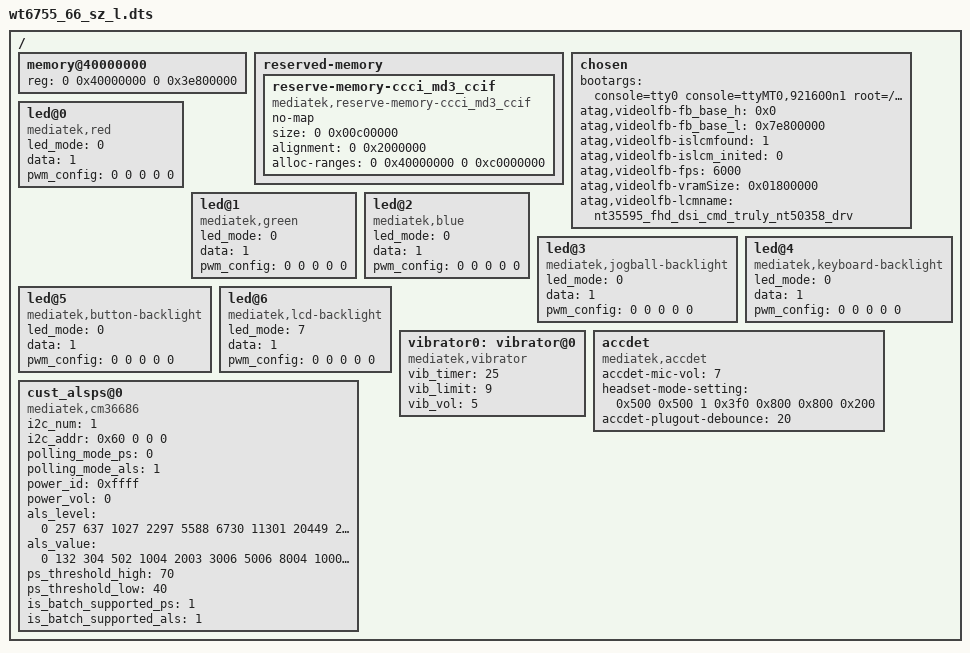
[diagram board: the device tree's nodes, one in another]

/dts-v1/;

#include "mt6755.dtsi"

/ {
	memory@40000000 {
		device_type = "memory";
		reg = <0 0x40000000 0 0x3e800000>;
	};

	reserved-memory {
		#address-cells = <2>;
		#size-cells = <2>;
		ranges;

		reserve-memory-ccci_md3_ccif {
			compatible = "mediatek,reserve-memory-ccci_md3_ccif";
			no-map;
			size = <0 0x00c00000>;
			alignment = <0 0x2000000>;
			alloc-ranges = <0 0x40000000 0 0xc0000000>;
		};
	};

	/* chosen */
	chosen {
		bootargs = "console=tty0 console=ttyMT0,921600n1 root=/dev/ram initrd=0x44000000,0x4b434e loglevel=8";

		/* fpga may has no lk, we need to specify display info here */
		/* fb buffer is reserved using this dts by memory node above */
		atag,videolfb-fb_base_h = <0x0>;
		atag,videolfb-fb_base_l = <0x7e800000>;
		atag,videolfb-islcmfound = <1>;
		/* because no lk, so lcm is not inited */
		atag,videolfb-islcm_inited = <0>;
		atag,videolfb-fps= <6000>;
		atag,videolfb-vramSize= <0x01800000>;
		atag,videolfb-lcmname= "nt35595_fhd_dsi_cmd_truly_nt50358_drv";
	};
	led@0 {
		compatible = "mediatek,red";
		led_mode = <0>;
		data = <1>;
		pwm_config = <0 0 0 0 0>;
	};
	led@1 {
		compatible = "mediatek,green";
		led_mode = <0>;
		data = <1>;
		pwm_config = <0 0 0 0 0>;
	};
	led@2 {
		compatible = "mediatek,blue";
		led_mode = <0>;
		data = <1>;
		pwm_config = <0 0 0 0 0>;
	};
	led@3 {
		compatible = "mediatek,jogball-backlight";
		led_mode = <0>;
		data = <1>;
		pwm_config = <0 0 0 0 0>;
	};
	led@4 {
		compatible = "mediatek,keyboard-backlight";
		led_mode = <0>;
		data = <1>;
		pwm_config = <0 0 0 0 0>;
	};
	led@5 {
		compatible = "mediatek,button-backlight";
		led_mode = <0>;
		data = <1>;
		pwm_config = <0 0 0 0 0>;
	};
	led@6 {
		compatible = "mediatek,lcd-backlight";
		led_mode = <7>;
		data = <1>;
		pwm_config = <0 0 0 0 0>;
	};
	vibrator0:vibrator@0 {
		compatible = "mediatek,vibrator";
		vib_timer = <25>;
		vib_limit = <9>;
		vib_vol= <5>;
	};
	accdet {
		compatible = "mediatek,accdet";
		accdet-mic-vol = <7>;
		headset-mode-setting = <0x500 0x500 1 0x3f0 0x800 0x800 0x200>;
		accdet-plugout-debounce = <20>;
	};
/*  start sensor */
	cust_alsps@0 {
		compatible 				= "mediatek,cm36686";
		i2c_num 				= <1>;
		i2c_addr 				= <0x60 0 0 0>;
		polling_mode_ps			= <0>;
		polling_mode_als		= <1>;
		power_id   				= <0xffff>;
		power_vol  				= <0>;
		/* Total has 15 level*/
		als_level  				= <0 257 637 1027 2297 5588 6730 11301 20449 25768 31122 45552 57937 57937 57937>;
		/*  Total has 16 range*/
		als_value  				= <0 132 304 502 1004 2003 3006 5006 8004 10000 12000 16000 20000 20000 20000 20000>;
		ps_threshold_high		=  <70>;
		ps_threshold_low		=  <40>;
		is_batch_supported_ps	= <1>;
		is_batch_supported_als	= <1>;
	};
/* end sensor */
};
